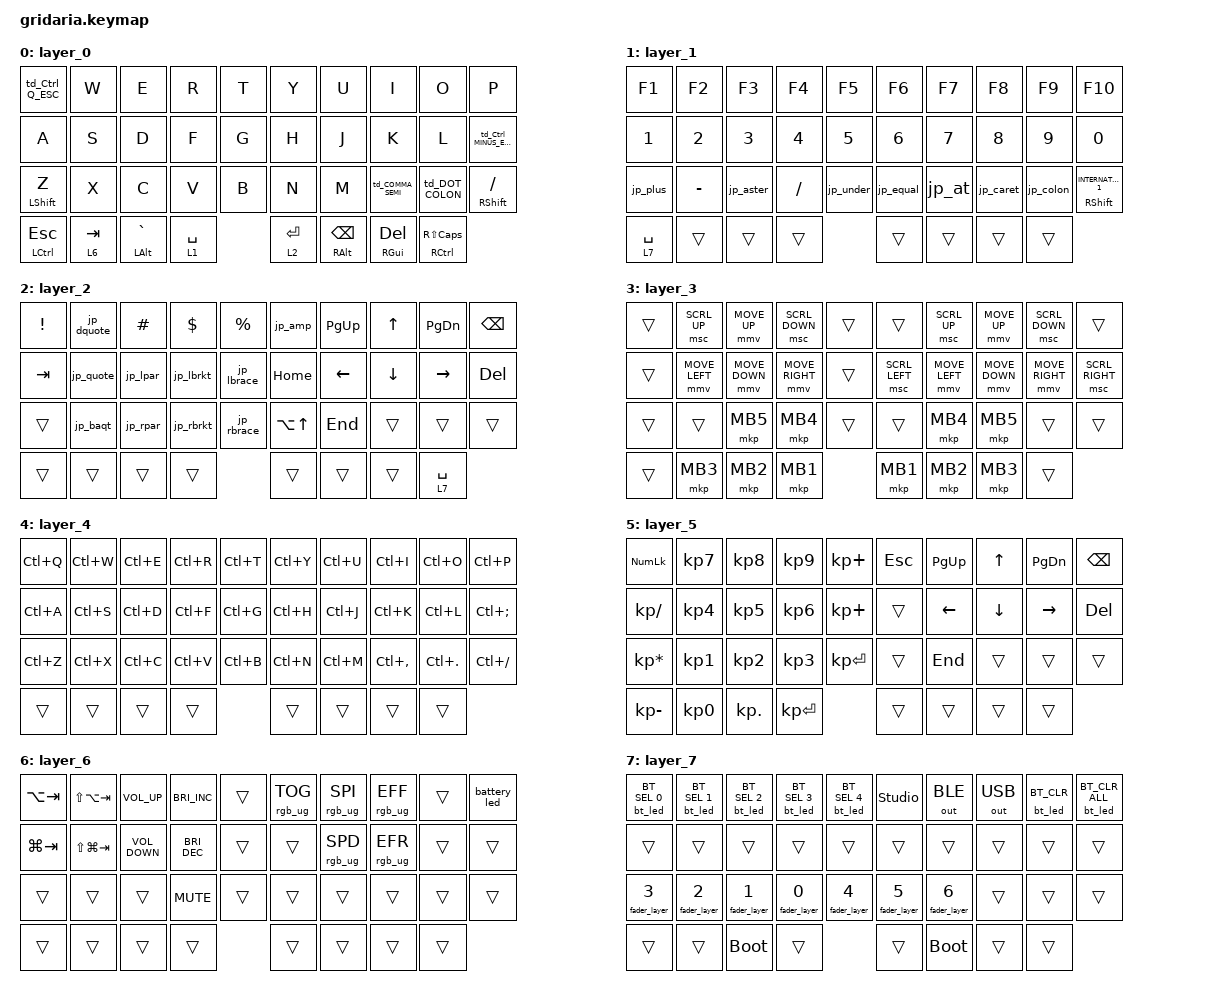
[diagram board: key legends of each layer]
#include <behaviors.dtsi>
#include <dt-bindings/zmk/bt.h>
#include <dt-bindings/zmk/keys.h>
#include <dt-bindings/zmk/mouse.h>
#include <dt-bindings/zmk/outputs.h>
#include <dt-bindings/zmk/rgb.h>

/* レイヤー・モディファイアカスタマイズ */

&lt {
    tapping-term-ms = <180>;
    quick-tap-ms = <160>;
    flavor = "hold-preferred";
};

&mt {
    tapping-term-ms = <180>;
    quick-tap-ms = <160>;
    flavor = "balanced";
};

/* ビヘイビア・キーマップ関連 */

/ {
    behaviors {
        bt_led: bt_led {
            compatible = "zmk,behavior-bt-led";
            #binding-cells = <2>;
            display-name = "Bluetooth LED";
        };

        battery_led: battery_led {
            compatible = "zmk,behavior-battery-led";
            #binding-cells = <0>;
            display-name = "Battery LED";
        };

        fader_layer: fader_layer {
            compatible = "zmk,behavior-fader-layer";
            #binding-cells = <1>;
            display-name = "Fader Layer";
        };

        /* タップダンス */
        td_COMMA_SEMI: tap_dance_1 {
            compatible = "zmk,behavior-tap-dance";
            #binding-cells = <0>;
            tapping-term-ms = <170>;
            bindings = <&kp COMMA>, <&kp SEMI>;

            label = ",";
        };

        td_DOT_COLON: tap_dance_2 {
            compatible = "zmk,behavior-tap-dance";
            #binding-cells = <0>;
            tapping-term-ms = <170>;
            bindings = <&kp DOT>, <&jp_colon>;

            label = ".";
        };

        td_Ctrl_MINUS_EQUAL: tap_dance_3 {
            compatible = "zmk,behavior-tap-dance";
            #binding-cells = <0>;
            tapping-term-ms = <170>;
            bindings = <&mt RCTRL MINUS>, <&jp_equal>;

            label = "/";
        };

        td_Ctrl_Q_ESC: tap_dance_4 {
            compatible = "zmk,behavior-tap-dance";
            #binding-cells = <0>;
            tapping-term-ms = <170>;
            bindings = <&mt RCTRL Q>, <&kp ESC>;

            label = "Q";
        };
        /* 日本語キーボード用マクロ定義 */

        jp_dquote: jp_dquote {
            compatible = "zmk,behavior-macro";
            #binding-cells = <0>;
            label = "JP_DQUOTE";
            bindings = <&kp AT>;
        };

        jp_amp: jp_amp {
            compatible = "zmk,behavior-macro";
            #binding-cells = <0>;
            label = "JP_AMP";
            bindings = <&kp CARET>;
        };

        jp_quote: jp_quote {
            compatible = "zmk,behavior-macro";
            #binding-cells = <0>;
            label = "JP_QUOTE";
            bindings = <&kp AMPERSAND>;
        };

        jp_equal: jp_equal {
            compatible = "zmk,behavior-macro";
            #binding-cells = <0>;
            label = "JP_EQUAL";
            bindings = <&kp UNDER>;
        };

        jp_caret: jp_caret {
            compatible = "zmk,behavior-macro";
            #binding-cells = <0>;
            label = "JP_CARET";
            bindings = <&kp EQUAL>;
        };

        jp_yen: jp_yen {
            compatible = "zmk,behavior-macro";
            #binding-cells = <0>;
            label = "JP_YEN";
            bindings = <&kp 0x89>;
        };

        jp_plus: jp_plus {
            compatible = "zmk,behavior-macro";
            #binding-cells = <0>;
            label = "JP_PLUS";
            bindings = <&kp COLON>;
        };

        jp_tilde: jp_tilde {
            compatible = "zmk,behavior-macro";
            #binding-cells = <0>;
            label = "JP_TILDE";
            bindings = <&kp PLUS>;
        };

        jp_pipe: jp_pipe {
            compatible = "zmk,behavior-macro";
            #binding-cells = <0>;
            label = "JP_PIPE";
            bindings = <&kp LS(0x89)>;
        };

        jp_at: jp_at {
            compatible = "zmk,behavior-macro";
            #binding-cells = <0>;
            label = "JP_AT";
            bindings = <&kp LEFT_BRACKET>;
        };

        jp_colon: jp_colon {
            compatible = "zmk,behavior-macro";
            #binding-cells = <0>;
            label = "JP_COLON";
            bindings = <&kp SINGLE_QUOTE>;
        };

        jp_aster: jp_aster {
            compatible = "zmk,behavior-macro";
            #binding-cells = <0>;
            label = "JP_ASTER";
            bindings = <&kp DOUBLE_QUOTES>;
        };

        jp_baqt: jp_baqt {
            compatible = "zmk,behavior-macro";
            #binding-cells = <0>;
            label = "JP_BAQT";
            bindings = <&kp LEFT_BRACE>;
        };

        jp_under: jp_under {
            compatible = "zmk,behavior-macro";
            #binding-cells = <0>;
            label = "JP_UNDER";
            bindings = <&kp LS(0x87)>;
        };

        jp_lbrkt: jp_lbrkt {
            compatible = "zmk,behavior-macro";
            #binding-cells = <0>;
            label = "JP_LBRACKET";
            bindings = <&kp RIGHT_BRACKET>;
        };

        jp_rbrkt: jp_rbrkt {
            compatible = "zmk,behavior-macro";
            #binding-cells = <0>;
            label = "JP_RBRACKET";
            bindings = <&kp BACKSLASH>;
        };

        jp_lpar: jp_lpar {
            compatible = "zmk,behavior-macro";
            #binding-cells = <0>;
            label = "JP_LPAREN";
            bindings = <&kp ASTERISK>;
        };

        jp_rpar: jp_rpar {
            compatible = "zmk,behavior-macro";
            #binding-cells = <0>;
            label = "JP_RPAREN";
            bindings = <&kp LEFT_PARENTHESIS>;
        };

        jp_lbrace: jp_lbrace {
            compatible = "zmk,behavior-macro";
            #binding-cells = <0>;
            label = "JP_LBRACE";
            bindings = <&kp RIGHT_BRACE>;
        };

        jp_rbrace: jp_rbrace {
            compatible = "zmk,behavior-macro";
            #binding-cells = <0>;
            label = "JP_RBRACE";
            bindings = <&kp PIPE>;
        };

        jp_kana: jp_kana {
            compatible = "zmk,behavior-macro";
            #binding-cells = <0>;
            label = "JP_KANA";
            bindings = <&kp LANGUAGE_1>;
        };

        jp_eisu: jp_eisu {
            compatible = "zmk,behavior-macro";
            #binding-cells = <0>;
            label = "JP_EISU";
            bindings = <&kp LANGUAGE_2>;
        };

        jp_hanzen: jp_hanzen {
            compatible = "zmk,behavior-macro";
            #binding-cells = <0>;
            label = "JP_HANZEN";
            bindings = <&kp GRAVE>;
        };
    };

    /* キーマップ */

    keymap {
        compatible = "zmk,keymap";

        layer_0 {
            bindings = <
                &td_Ctrl_Q_ESC   &kp W      &kp E      &kp R      &kp T      &kp Y      &kp U      &kp I      &kp O      &kp P
                &kp A         &kp S      &kp D      &kp F      &kp G      &kp H      &kp J      &kp K      &kp L      &td_Ctrl_MINUS_EQUAL
                &mt LSHFT Z   &kp X      &kp C      &kp V      &kp B      &kp N      &kp M      &td_COMMA_SEMI     &td_DOT_COLON     &mt RSHFT SLASH
                &mt LCTRL ESC  &lt 6 TAB &mt LALT GRAVE &lt 1 SPACE  &lt 2 RET &mt RALT BSPC &mt RGUI DEL &mt RCTRL RS(CAPSLOCK)
            >;
        };

        layer_1 {
            bindings = <
                &kp F1       &kp F2       &kp F3       &kp F4       &kp F5       &kp F6       &kp F7       &kp F8       &kp F9       &kp F10
                &kp N1       &kp N2       &kp N3       &kp N4       &kp N5       &kp N6       &kp N7       &kp N8       &kp N9       &kp N0
                &jp_plus     &kp MINUS    &jp_aster    &kp SLASH    &jp_under    &jp_equal    &jp_at       &jp_caret    &jp_colon    &mt RSHFT INTERNATIONAL_1
                &lt 7 SPACE       &trans       &trans       &trans                    &trans       &trans       &trans       &trans
            >;
        };

        layer_2 {
            bindings = <
                &kp EXCL    &jp_dquote  &kp HASH    &kp DLLR    &kp PRCNT   &jp_amp     &kp PG_UP   &kp UP      &kp PG_DN   &kp BSPC
                &kp TAB     &jp_quote   &jp_lpar    &jp_lbrkt   &jp_lbrace  &kp HOME    &kp LEFT    &kp DOWN    &kp RIGHT   &kp DEL
                &trans      &jp_baqt    &jp_rpar    &jp_rbrkt   &jp_rbrace  &kp LA(UP)  &kp END     &trans      &trans      &trans
                &trans      &trans      &trans      &trans                              &trans      &trans      &trans      &lt 7 SPACE
            >;
        };

        layer_3 {
            bindings = <
                &trans      &msc SCRL_UP    &mmv MOVE_UP    &msc SCRL_DOWN  &trans      &trans          &msc SCRL_UP    &mmv MOVE_UP    &msc SCRL_DOWN  &trans
                &trans      &mmv MOVE_LEFT  &mmv MOVE_DOWN  &mmv MOVE_RIGHT &trans      &msc SCRL_LEFT  &mmv MOVE_LEFT  &mmv MOVE_DOWN  &mmv MOVE_RIGHT &msc SCRL_RIGHT
                &trans      &trans          &mkp MB5        &mkp MB4        &trans      &trans          &mkp MB4        &mkp MB5        &trans          &trans
                &trans      &mkp MB3        &mkp MB2        &mkp MB1                                   &mkp MB1       &mkp MB2        &mkp MB3        &trans
            >;
        };

        layer_4 {
            bindings = <
                &kp LC(Q) &kp LC(W) &kp LC(E) &kp LC(R) &kp LC(T) &kp LC(Y) &kp LC(U) &kp LC(I) &kp LC(O) &kp LC(P)
                &kp LC(A) &kp LC(S) &kp LC(D) &kp LC(F) &kp LC(G) &kp LC(H) &kp LC(J) &kp LC(K) &kp LC(L) &kp LC(SEMI)
                &kp LC(Z) &kp LC(X) &kp LC(C) &kp LC(V) &kp LC(B) &kp LC(N) &kp LC(M) &kp LC(COMMA) &kp LC(DOT) &kp LC(SLASH)
                &trans    &trans    &trans    &trans                        &trans    &trans    &trans    &trans
            >;
        };

        layer_5 {
            bindings = <
                &kp KP_NUM      &kp KP_N7   &kp KP_N8   &kp KP_N9    &kp KP_PLUS    &kp ESC      &kp PG_UP   &kp UP      &kp PG_DN   &kp BSPC
                &kp KP_SLASH    &kp KP_N4   &kp KP_N5   &kp KP_N6    &kp KP_PLUS    &trans       &kp LEFT    &kp DOWN    &kp RIGHT   &kp DEL
                &kp KP_ASTERISK &kp KP_N1   &kp KP_N2   &kp KP_N3    &kp KP_ENTER   &trans       &kp END     &trans      &trans      &trans
                &kp KP_MINUS    &kp KP_N0   &kp KP_DOT  &kp KP_ENTER                             &trans      &trans      &trans      &trans
            >;
        };

        /* The first seven transparent positions store the fader targets for Studio. */
        layer_6 {
            bindings = <
                &kp LA(TAB) &kp LS(LA(TAB)) &kp C_VOLUME_UP   &kp C_BRIGHTNESS_INC &trans     &rgb_ug RGB_TOG &rgb_ug RGB_SPI &rgb_ug RGB_EFF &trans  &battery_led
                &kp LG(TAB) &kp LS(LG(TAB)) &kp C_VOLUME_DOWN &kp C_BRIGHTNESS_DEC &trans     &trans          &rgb_ug RGB_SPD &rgb_ug RGB_EFR &trans  &trans
                &trans &trans &trans            &kp C_MUTE           &trans     &trans          &trans          &trans          &trans  &trans
                &trans &trans &trans            &trans                                          &trans          &trans          &trans  &trans
            >;
        };

        layer_7 {
            bindings = <
                &bt_led BT_SEL 0    &bt_led BT_SEL 1    &bt_led BT_SEL 2    &bt_led BT_SEL 3    &bt_led BT_SEL 4    &studio_unlock  &out OUT_BLE    &out OUT_USB    &bt_led BT_CLR  &bt_led BT_CLR_ALL
                &trans          &trans          &trans          &trans          &trans          &trans          &trans          &trans          &trans      &trans
                &fader_layer 3  &fader_layer 2  &fader_layer 1  &fader_layer 0  &fader_layer 4  &fader_layer 5  &fader_layer 6  &trans    &trans      &trans
                &trans          &trans          &bootloader     &trans                                          &trans          &bootloader     &trans      &trans
            >;
        };
    };
};
